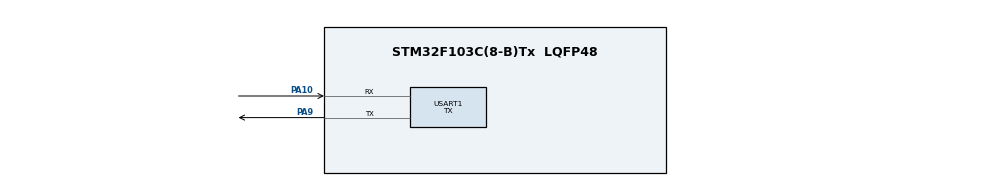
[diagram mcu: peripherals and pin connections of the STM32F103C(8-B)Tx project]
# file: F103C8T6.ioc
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FREERTOS.INCLUDE_eTaskGetState=1
FREERTOS.INCLUDE_vTaskDelayUntil=1
FREERTOS.Tasks01=defaultTask,0,128,StartDefaultTask,Default,NULL,Dynamic,NULL,NULL
FREERTOS.configMAX_TASK_NAME_LEN=32
FREERTOS.configUSE_COUNTING_SEMAPHORES=1
FREERTOS.configUSE_NEWLIB_REENTRANT=1
FREERTOS.configUSE_TIMERS=1
Mcu.Family=STM32F1
Mcu.Name=STM32F103C(8-B)Tx
Mcu.Package=LQFP48
NVIC.PriorityGroup=NVIC_PRIORITYGROUP_4
NVIC.TIM4_IRQn=true\:0\:0\:true\:false\:true\:false\:false\:true\:true
NVIC.TimeBase=TIM4_IRQn
NVIC.TimeBaseIP=TIM4
PA10.Mode=Asynchronous
PA10.Signal=USART1_RX
PA13.Mode=Serial_Wire
PA13.Signal=SYS_JTMS-SWDIO
PA14.Mode=Serial_Wire
PA14.Signal=SYS_JTCK-SWCLK
PA9.Mode=Asynchronous
PA9.Signal=USART1_TX
PD0-OSC_IN.Mode=HSE-External-Oscillator
PD0-OSC_IN.Signal=RCC_OSC_IN
PD1-OSC_OUT.Mode=HSE-External-Oscillator
PD1-OSC_OUT.Signal=RCC_OSC_OUT
ProjectManager.HeapSize=0x200
ProjectManager.StackSize=0x400
ProjectManager.TargetToolchain=CMake
RCC.AHBFreq_Value=72000000
RCC.APB1CLKDivider=RCC_HCLK_DIV2
RCC.APB1Freq_Value=36000000
RCC.APB1TimFreq_Value=72000000
RCC.APB2Freq_Value=72000000
RCC.APB2TimFreq_Value=72000000
RCC.HCLKFreq_Value=72000000
RCC.PLLMUL=RCC_PLL_MUL9
RCC.PLLSourceVirtual=RCC_PLLSOURCE_HSE
RCC.SYSCLKFreq_VALUE=72000000
RCC.SYSCLKSource=RCC_SYSCLKSOURCE_PLLCLK
RCC.USBFreq_Value=72000000
STMicroelectronics.X-CUBE-ALGOBUILD.1.4.0.LibraryCcDSPOoLibraryJjDSPOoLibrary=true
USART1.Mode=MODE_TX
USART1.VirtualMode=VM_ASYNC
VP_FREERTOS_VS_CMSIS_V1.Mode=CMSIS_V1
VP_STMicroelectronics.X-CUBE-ALGOBUILD_VS_DSPOoLibraryJjLibrary_1.4.0_1.4.0.Mode=DSPOoLibraryJjLibrary
VP_SYS_VS_tim4.Mode=TIM4
board=custom

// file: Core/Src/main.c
/* USER CODE BEGIN Header */
/**
  ******************************************************************************
  * @file           : main.c
  * @brief          : Main program body
  ******************************************************************************
  * @attention
  *
  * Copyright (c) 2026 STMicroelectronics.
  * All rights reserved.
  *
  * This software is licensed under terms that can be found in the LICENSE file
  * in the root directory of this software component.
  * If no LICENSE file comes with this software, it is provided AS-IS.
  *
  ******************************************************************************
  */
/* USER CODE END Header */
#include "main.h"
#include "cmsis_os.h"
#include "usart.h"
#include "gpio.h"

/* USER CODE BEGIN Includes */

#include "rmdev_test.h"

/* USER CODE END Includes */

void SystemClock_Config(void);
void MX_FREERTOS_Init(void);

int main(void)
{

  /* USER CODE BEGIN 1 */

  testInit(NULL);

  /* USER CODE END 1 */

  /* MCU Configuration--------------------------------------------------------*/

  /* Reset of all peripherals, Initializes the Flash interface and the Systick. */
  HAL_Init();

  /* Configure the system clock */
  SystemClock_Config();

  /* Initialize all configured peripherals */
  MX_GPIO_Init();
  MX_USART1_UART_Init();
  /* USER CODE BEGIN 2 */

  testEntry();

  /* USER CODE END 2 */

  /* Call init function for freertos objects (in cmsis_os2.c) */
  MX_FREERTOS_Init();

  /* Start scheduler */
  osKernelStart();

  /* We should never get here as control is now taken by the scheduler */

  /* Infinite loop */
  while (1)
  {

  }
}

void SystemClock_Config(void)
{
  LL_FLASH_SetLatency(LL_FLASH_LATENCY_2);
  while(LL_FLASH_GetLatency()!= LL_FLASH_LATENCY_2)
  {
  }
  LL_RCC_HSE_Enable();

   /* Wait till HSE is ready */
  while(LL_RCC_HSE_IsReady() != 1)
  {

  }
  LL_RCC_PLL_ConfigDomain_SYS(LL_RCC_PLLSOURCE_HSE_DIV_1, LL_RCC_PLL_MUL_9);
  LL_RCC_PLL_Enable();

   /* Wait till PLL is ready */
  while(LL_RCC_PLL_IsReady() != 1)
  {

  }
  LL_RCC_SetAHBPrescaler(LL_RCC_SYSCLK_DIV_1);
  LL_RCC_SetAPB1Prescaler(LL_RCC_APB1_DIV_2);
  LL_RCC_SetAPB2Prescaler(LL_RCC_APB2_DIV_1);
  LL_RCC_SetSysClkSource(LL_RCC_SYS_CLKSOURCE_PLL);

   /* Wait till System clock is ready */
  while(LL_RCC_GetSysClkSource() != LL_RCC_SYS_CLKSOURCE_STATUS_PLL)
  {

  }
  LL_SetSystemCoreClock(72000000);

   /* Update the time base */
  if (HAL_InitTick (TICK_INT_PRIORITY) != HAL_OK)
  {
    Error_Handler();
  }
}

void HAL_TIM_PeriodElapsedCallback(TIM_HandleTypeDef *htim)
{
  if (htim->Instance == TIM4)
  {
    HAL_IncTick();
  }
}

void Error_Handler(void)
{
  __disable_irq();
  while (1)
  {
  }
}

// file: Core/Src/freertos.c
/* USER CODE BEGIN Header */
/**
  ******************************************************************************
  * File Name          : freertos.c
  * Description        : Code for freertos applications
  ******************************************************************************
  * @attention
  *
  * Copyright (c) 2026 STMicroelectronics.
  * All rights reserved.
  *
  * This software is licensed under terms that can be found in the LICENSE file
  * in the root directory of this software component.
  * If no LICENSE file comes with this software, it is provided AS-IS.
  *
  ******************************************************************************
  */
/* USER CODE END Header */

#include "FreeRTOS.h"
#include "task.h"
#include "main.h"
#include "cmsis_os.h"

osThreadId defaultTaskHandle;

void StartDefaultTask(void const * argument);

void MX_FREERTOS_Init(void); /* (MISRA C 2004 rule 8.1) */

/* GetIdleTaskMemory prototype (linked to static allocation support) */
void vApplicationGetIdleTaskMemory( StaticTask_t **ppxIdleTaskTCBBuffer, StackType_t **ppxIdleTaskStackBuffer, uint32_t *pulIdleTaskStackSize );

/* GetTimerTaskMemory prototype (linked to static allocation support) */
void vApplicationGetTimerTaskMemory( StaticTask_t **ppxTimerTaskTCBBuffer, StackType_t **ppxTimerTaskStackBuffer, uint32_t *pulTimerTaskStackSize );

/* USER CODE BEGIN GET_IDLE_TASK_MEMORY */
static StaticTask_t xIdleTaskTCBBuffer;
static StackType_t xIdleStack[configMINIMAL_STACK_SIZE];

void vApplicationGetIdleTaskMemory( StaticTask_t **ppxIdleTaskTCBBuffer, StackType_t **ppxIdleTaskStackBuffer, uint32_t *pulIdleTaskStackSize )
{
  *ppxIdleTaskTCBBuffer = &xIdleTaskTCBBuffer;
  *ppxIdleTaskStackBuffer = &xIdleStack[0];
  *pulIdleTaskStackSize = configMINIMAL_STACK_SIZE;
  /* place for user code */
}
/* USER CODE END GET_IDLE_TASK_MEMORY */

/* USER CODE BEGIN GET_TIMER_TASK_MEMORY */
static StaticTask_t xTimerTaskTCBBuffer;
static StackType_t xTimerStack[configTIMER_TASK_STACK_DEPTH];

void vApplicationGetTimerTaskMemory( StaticTask_t **ppxTimerTaskTCBBuffer, StackType_t **ppxTimerTaskStackBuffer, uint32_t *pulTimerTaskStackSize )
{
  *ppxTimerTaskTCBBuffer = &xTimerTaskTCBBuffer;
  *ppxTimerTaskStackBuffer = &xTimerStack[0];
  *pulTimerTaskStackSize = configTIMER_TASK_STACK_DEPTH;
  /* place for user code */
}
/* USER CODE END GET_TIMER_TASK_MEMORY */

void MX_FREERTOS_Init(void) {

  /* Create the thread(s) */
  /* definition and creation of defaultTask */
  osThreadDef(defaultTask, StartDefaultTask, osPriorityNormal, 0, 128);
  defaultTaskHandle = osThreadCreate(osThread(defaultTask), NULL);

}

void StartDefaultTask(void const * argument)
{
  for(;;)
  {
    osDelay(1);
  }
}
